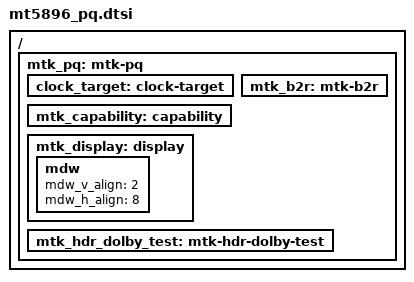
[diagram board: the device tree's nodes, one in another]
// SPDX-License-Identifier: (GPL-2.0 OR BSD-3-Clause)
/*
 * Copyright (c) 2020 MediaTek Inc.
 */

/ {
	mtk_pq: mtk-pq {
		clock_target: clock-target {
		};
		mtk_capability: capability {
		};
		mtk_display: display {
			mdw {
				mdw_v_align = <2>;			/* in pixel */
				mdw_h_align = <8>;			/* in pixel */
			};
		};
		mtk_b2r: mtk-b2r {
		};
		mtk_hdr_dolby_test: mtk-hdr-dolby-test {
		};
	};
};
